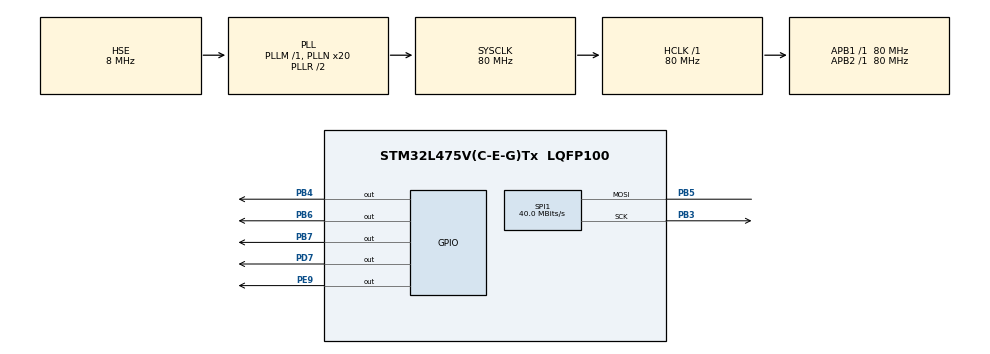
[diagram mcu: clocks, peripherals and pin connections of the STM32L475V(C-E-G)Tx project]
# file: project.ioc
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Mcu.Family=STM32L4
Mcu.Name=STM32L475V(C-E-G)Tx
Mcu.Package=LQFP100
NVIC.PriorityGroup=NVIC_PRIORITYGROUP_4
PB3\ (JTDO-TRACESWO).Mode=Simplex_Bidirectional_Master
PB3\ (JTDO-TRACESWO).Signal=SPI1_SCK
PB4\ (NJTRST).Signal=GPIO_Output
PB5.Mode=Simplex_Bidirectional_Master
PB5.Signal=SPI1_MOSI
PB6.Signal=GPIO_Output
PB7.Signal=GPIO_Output
PC14-OSC32_IN\ (PC14).Mode=LSE-External-Oscillator
PC14-OSC32_IN\ (PC14).Signal=RCC_OSC32_IN
PC15-OSC32_OUT\ (PC15).Mode=LSE-External-Oscillator
PC15-OSC32_OUT\ (PC15).Signal=RCC_OSC32_OUT
PD7.Signal=GPIO_Output
PE9.Signal=GPIO_Output
PH0-OSC_IN\ (PH0).Mode=HSE-External-Oscillator
PH0-OSC_IN\ (PH0).Signal=RCC_OSC_IN
PH1-OSC_OUT\ (PH1).Mode=HSE-External-Oscillator
PH1-OSC_OUT\ (PH1).Signal=RCC_OSC_OUT
ProjectManager.HeapSize=0x200
ProjectManager.StackSize=0x400
ProjectManager.TargetToolchain=MDK-ARM V5.32
RCC.ADCFreq_Value=32000000
RCC.AHBFreq_Value=80000000
RCC.APB1Freq_Value=80000000
RCC.APB1TimFreq_Value=80000000
RCC.APB2Freq_Value=80000000
RCC.APB2TimFreq_Value=80000000
RCC.CortexFreq_Value=80000000
RCC.HCLKFreq_Value=80000000
RCC.HSE_VALUE=8000000
RCC.HSI_VALUE=16000000
RCC.MSIAutoCalibration=DISABLED
RCC.MSI_VALUE=4000000
RCC.PLLN=20
RCC.PLLSourceVirtual=RCC_PLLSOURCE_HSE
RCC.SYSCLKFreq_VALUE=80000000
RCC.SYSCLKSource=RCC_SYSCLKSOURCE_PLLCLK
RCC.USBFreq_Value=32000000
RCC.VCOOutputFreq_Value=160000000
SPI1.CLKPhase=SPI_PHASE_2EDGE
SPI1.CLKPolarity=SPI_POLARITY_HIGH
SPI1.CalculateBaudRate=40.0 MBits/s
SPI1.DataSize=SPI_DATASIZE_8BIT
SPI1.Direction=SPI_DIRECTION_1LINE
SPI1.Mode=SPI_MODE_MASTER
SPI1.VirtualType=VM_MASTER
board=custom

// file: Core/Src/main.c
/* USER CODE BEGIN Header */
/**
  ******************************************************************************
  * @file           : main.c
  * @brief          : Main program body
  ******************************************************************************
  * @attention
  *
  * Copyright (c) 2023 STMicroelectronics.
  * All rights reserved.
  *
  * This software is licensed under terms that can be found in the LICENSE file
  * in the root directory of this software component.
  * If no LICENSE file comes with this software, it is provided AS-IS.
  *
  ******************************************************************************
  */
/* USER CODE END Header */
#include "main.h"

SPI_HandleTypeDef hspi1;

void SystemClock_Config(void);
static void MX_GPIO_Init(void);
static void MX_SPI1_Init(void);

/* USER CODE BEGIN 0 */
#define LED_B_TogglePin     HAL_GPIO_TogglePin(GPIOE,GPIO_PIN_9)
/* USER CODE END 0 */

int main(void)
{
  /* USER CODE BEGIN 1 */

	uint8_t color = 0;
  /* USER CODE END 1 */

  /* MCU Configuration--------------------------------------------------------*/

  /* Reset of all peripherals, Initializes the Flash interface and the Systick. */
  HAL_Init();

  /* Configure the system clock */
  SystemClock_Config();

  /* Initialize all configured peripherals */
  MX_GPIO_Init();
  MX_SPI1_Init();
  /* USER CODE BEGIN 2 */
	delay_init(80);
	LCD_Init();
	LVGL_Init();
	//LVGL_CentralButton();
	TestExample();
  /* USER CODE END 2 */

  /* Infinite loop */
  /* USER CODE BEGIN WHILE */
  while (1)
  {
		/*switch(color % 12)
        {
            case 0:
                LCD_Clear(WHITE);
                break;
            case 1:
                LCD_Clear(GREEN);
                break;
            case 2:
                LCD_Clear(BLUE);
                break;
            case 3:
                LCD_Draw_ColorPoint(120,120,GREEN);;
                break;
            case 4:
                LCD_DrawLine(20,20,180,160,RED);
                break;
            case 5:
                LCD_Clear(GREEN);
                break;
            case 6:
                LCD_Clear(CYAN);
                break;
            case 7:
                LCD_Clear(YELLOW);
                break;
            case 8:
                LCD_Clear(BRRED);
                break;
            case 9:
                LCD_Clear(GRAY);
                break;
            case 10:
                LCD_Clear(LGRAY);
                break;
            case 11:
                LCD_Clear(BROWN);
                break;
            default :
                color = 0;
                break;
        }
			color++;
			delay_ms(1000);
				LED_B_TogglePin;
				*/
				 lv_timer_handler();
				 delay_ms(1000);
    /* USER CODE END WHILE */

  }
}

void SystemClock_Config(void)
{
  RCC_OscInitTypeDef RCC_OscInitStruct = {0};
  RCC_ClkInitTypeDef RCC_ClkInitStruct = {0};

  /** Configure the main internal regulator output voltage
  */
  if (HAL_PWREx_ControlVoltageScaling(PWR_REGULATOR_VOLTAGE_SCALE1) != HAL_OK)
  {
    Error_Handler();
  }

  /** Initializes the RCC Oscillators according to the specified parameters
  * in the RCC_OscInitTypeDef structure.
  */
  RCC_OscInitStruct.OscillatorType = RCC_OSCILLATORTYPE_HSE;
  RCC_OscInitStruct.HSEState = RCC_HSE_ON;
  RCC_OscInitStruct.PLL.PLLState = RCC_PLL_ON;
  RCC_OscInitStruct.PLL.PLLSource = RCC_PLLSOURCE_HSE;
  RCC_OscInitStruct.PLL.PLLM = 1;
  RCC_OscInitStruct.PLL.PLLN = 20;
  RCC_OscInitStruct.PLL.PLLP = RCC_PLLP_DIV7;
  RCC_OscInitStruct.PLL.PLLQ = RCC_PLLQ_DIV2;
  RCC_OscInitStruct.PLL.PLLR = RCC_PLLR_DIV2;
  if (HAL_RCC_OscConfig(&RCC_OscInitStruct) != HAL_OK)
  {
    Error_Handler();
  }

  /** Initializes the CPU, AHB and APB buses clocks
  */
  RCC_ClkInitStruct.ClockType = RCC_CLOCKTYPE_HCLK|RCC_CLOCKTYPE_SYSCLK
                              |RCC_CLOCKTYPE_PCLK1|RCC_CLOCKTYPE_PCLK2;
  RCC_ClkInitStruct.SYSCLKSource = RCC_SYSCLKSOURCE_PLLCLK;
  RCC_ClkInitStruct.AHBCLKDivider = RCC_SYSCLK_DIV1;
  RCC_ClkInitStruct.APB1CLKDivider = RCC_HCLK_DIV1;
  RCC_ClkInitStruct.APB2CLKDivider = RCC_HCLK_DIV1;

  if (HAL_RCC_ClockConfig(&RCC_ClkInitStruct, FLASH_LATENCY_4) != HAL_OK)
  {
    Error_Handler();
  }
}

static void MX_SPI1_Init(void)
{

  /* SPI1 parameter configuration*/
  hspi1.Instance = SPI1;
  hspi1.Init.Mode = SPI_MODE_MASTER;
  hspi1.Init.Direction = SPI_DIRECTION_1LINE;
  hspi1.Init.DataSize = SPI_DATASIZE_8BIT;
  hspi1.Init.CLKPolarity = SPI_POLARITY_HIGH;
  hspi1.Init.CLKPhase = SPI_PHASE_2EDGE;
  hspi1.Init.NSS = SPI_NSS_SOFT;
  hspi1.Init.BaudRatePrescaler = SPI_BAUDRATEPRESCALER_2;
  hspi1.Init.FirstBit = SPI_FIRSTBIT_MSB;
  hspi1.Init.TIMode = SPI_TIMODE_DISABLE;
  hspi1.Init.CRCCalculation = SPI_CRCCALCULATION_DISABLE;
  hspi1.Init.CRCPolynomial = 7;
  hspi1.Init.CRCLength = SPI_CRC_LENGTH_DATASIZE;
  hspi1.Init.NSSPMode = SPI_NSS_PULSE_DISABLE;
  if (HAL_SPI_Init(&hspi1) != HAL_OK)
  {
    Error_Handler();
  }

}

static void MX_GPIO_Init(void)
{
  GPIO_InitTypeDef GPIO_InitStruct = {0};

  /* GPIO Ports Clock Enable */
  __HAL_RCC_GPIOC_CLK_ENABLE();
  __HAL_RCC_GPIOH_CLK_ENABLE();
  __HAL_RCC_GPIOE_CLK_ENABLE();
  __HAL_RCC_GPIOD_CLK_ENABLE();
  __HAL_RCC_GPIOB_CLK_ENABLE();

  /*Configure GPIO pin Output Level */
  HAL_GPIO_WritePin(GPIOE, GPIO_PIN_9, GPIO_PIN_RESET);

  /*Configure GPIO pin Output Level */
  HAL_GPIO_WritePin(GPIOD, GPIO_PIN_7, GPIO_PIN_RESET);

  /*Configure GPIO pin Output Level */
  HAL_GPIO_WritePin(GPIOB, GPIO_PIN_4|GPIO_PIN_6|GPIO_PIN_7, GPIO_PIN_RESET);

  /*Configure GPIO pin : PE9 */
  GPIO_InitStruct.Pin = GPIO_PIN_9;
  GPIO_InitStruct.Mode = GPIO_MODE_OUTPUT_PP;
  GPIO_InitStruct.Pull = GPIO_NOPULL;
  GPIO_InitStruct.Speed = GPIO_SPEED_FREQ_LOW;
  HAL_GPIO_Init(GPIOE, &GPIO_InitStruct);

  /*Configure GPIO pin : PD7 */
  GPIO_InitStruct.Pin = GPIO_PIN_7;
  GPIO_InitStruct.Mode = GPIO_MODE_OUTPUT_PP;
  GPIO_InitStruct.Pull = GPIO_NOPULL;
  GPIO_InitStruct.Speed = GPIO_SPEED_FREQ_LOW;
  HAL_GPIO_Init(GPIOD, &GPIO_InitStruct);

  /*Configure GPIO pins : PB4 PB6 PB7 */
  GPIO_InitStruct.Pin = GPIO_PIN_4|GPIO_PIN_6|GPIO_PIN_7;
  GPIO_InitStruct.Mode = GPIO_MODE_OUTPUT_PP;
  GPIO_InitStruct.Pull = GPIO_NOPULL;
  GPIO_InitStruct.Speed = GPIO_SPEED_FREQ_LOW;
  HAL_GPIO_Init(GPIOB, &GPIO_InitStruct);

}

void Error_Handler(void)
{
  __disable_irq();
  while (1)
  {
  }
}
